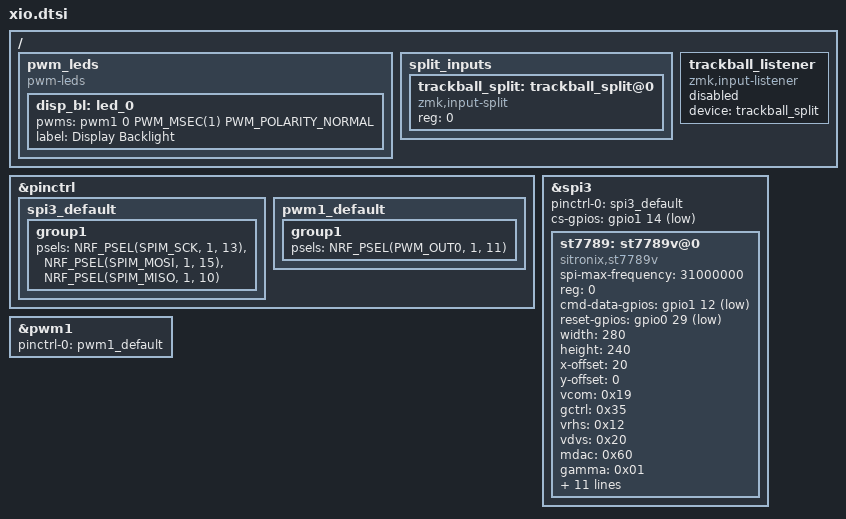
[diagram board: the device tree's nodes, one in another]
/* boards/shields/split_ergo60pct/xio.dtsi */

/ {
    /* (A) バックライト・マネージャー(Cコード)用: pwm-leds構造 */
    pwm_leds: pwm_leds {
        compatible = "pwm-leds";
        disp_bl: led_0 {
            pwms = <&pwm1 0 PWM_MSEC(1) PWM_POLARITY_NORMAL>;
            label = "Display Backlight";
        };
    };

    /* (B) トラックボール/タッチパネル入力の受信口 */
    split_inputs {
        #address-cells = <1>;
        #size-cells = <0>;
        trackball_split: trackball_split@0 {
            compatible = "zmk,input-split";
            reg = <0>;
        };
    };

    /* 【重要】ここがエラーの原因となっていた『実体』の定義です */
    trackball_listener: trackball_listener {
        compatible = "zmk,input-listener";
        status = "disabled"; /* overlay側で okay にします */
        device = <&trackball_split>;
    };
};

/* --- XIAO BLE ピン定義 --- */
&pinctrl {
    spi3_default: spi3_default {
        group1 {
            psels = <NRF_PSEL(SPIM_SCK, 1, 13)>,
                    <NRF_PSEL(SPIM_MOSI, 1, 15)>,
                    <NRF_PSEL(SPIM_MISO, 1, 10)>;
        };
    };
    pwm1_default: pwm1_default {
        group1 {
            psels = <NRF_PSEL(PWM_OUT0, 1, 11)>;
        };
    };
};

/* --- ST7789 ディスプレイ (必須パラメータ完備) --- */
&spi3 {
    status = "okay";
    pinctrl-0 = <&spi3_default>;
    pinctrl-names = "default";
    
    /* 修正: D9 は XIAO BLE では P1.14 に該当します */
    cs-gpios = <&gpio1 14 GPIO_ACTIVE_LOW>;

    st7789: st7789v@0 {
        compatible = "sitronix,st7789v";
        spi-max-frequency = <31000000>;
        reg = <0>;
 
        
        /* 修正: D7 は XIAO BLE では P1.12 に該当します */
        cmd-data-gpios = <&gpio1 12 GPIO_ACTIVE_LOW>;
        
        /* 修正: D3 は XIAO BLE では P0.29 に該当します */
        reset-gpios = <&gpio0 29 GPIO_ACTIVE_LOW>;
        
        width = <280>;
        height = <240>;
        x-offset = <20>;
        y-offset = <0>;

        /* Zephyr 3.5 必須パラメータ */
        vcom = <0x19>;
        gctrl = <0x35>;
        vrhs = <0x12>;
        vdvs = <0x20>;
        mdac = <0x60>;
        gamma = <0x01>;
        colmod = <0x05>;
        lcm = <0x2c>;
        porch-param = [ 0c 0c 00 33 33 ];
        cmd2en-param = [ 5a 69 02 01 ];
        pwctrl1-param = [ a4 a1 ];
        pvgam-param = [ d0 04 0d 11 13 2b 3f 54 4c 18 0d 0b 1f 23 ];
        nvgam-param = [ d0 04 0c 11 13 2c 3f 44 51 2f 1f 1f 20 23 ];
        ram-param = [ 00 f0 ];
        rgb-param = [ cd 08 14 ];
    };
};

/* APDS9960 照度センサー */
/*
&i2c0 {

    status = "okay";

    apds9960: apds9960@39 {

        compatible = "avago,apds9960";

        reg = <0x39>;

        status = "okay";

        int-gpios = <&gpio0 28 (GPIO_ACTIVE_LOW | GPIO_PULL_UP)>;

    };

};
*/


&pwm1 {
    status = "okay";
    pinctrl-0 = <&pwm1_default>;
    pinctrl-names = "default";
};
